AUTOSAR XML (schema 4-3-0)
standard types defined: uint8, uint8_DataConstr, uint16
package /ComponentTypes/FcaAdapSWC/Constants
  constant specification CS_FCAAdap_FCA_Output: value-spec=fields=[FCA_WrngLvlSta:0, FCA_VehStpReq:0, FCA_StbltActvReq:0, FCA_DclReqVal:0, FCA_PrefillActvReq:0, FCA_FullActvReq:0, FCA_TimetoCllsn:0, FCA_WrngTrgtDis:0, FCA_PartialActvReq:0]
package /ComponentTypes/FcaAdapSWC/DataTypes
  impl type FCA_OUTPUTS_T: category=STRUCTURE, type-emitter=RTE
    9 x element, all with category=TYPE_REFERENCE, implementation-data-type=uint8:
      FCA_WrngLvlSta
      FCA_VehStpReq
      FCA_StbltActvReq
      FCA_DclReqVal
      FCA_PrefillActvReq
      FCA_FullActvReq
      FCA_TimetoCllsn
      FCA_WrngTrgtDis
      FCA_PartialActvReq
package /ComponentTypes/FcaAdapSWC/PortInterfaces
  sender receiver interface IF_FCA_OUTPUT: invalidation-policy{data-element=DE_FcaAdapOutput, handle-invalid=DONT-INVALIDATE}
    data DE_FcaAdapOutput: type=FCA_OUTPUTS_T
package /ComponentTypes/HkmcVehicleOutputSWC
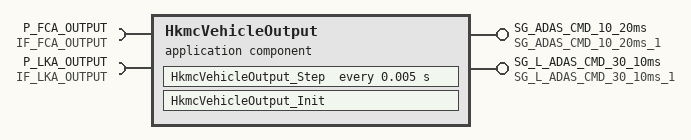
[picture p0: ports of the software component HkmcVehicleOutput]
  application sw component type HkmcVehicleOutput
    provide port SG_ADAS_CMD_10_20ms: nonqueued-sender-com-spec{data-element=SG_ADAS_CMD_10_20ms, init-value=fields=[ADAS_CMD_AlvCnt10Val:0, ADAS_CMD_Crc10Val:65535, FCA_DclReqVal:0, FCA_FullActvReq:0, FCA_HydrlcBstAsstReq:0, FCA_Jnctn_OnOffEquipSta:0, FCA_OnOffEquipSta:0, FCA_PartialActvReq:0, FCA_PrefillActvReq:0, FCA_RelVel:0, FCA_SnstvtyModRetVal:0, FCA_StbltActvReq:0, FCA_SysFlrSta:0, FCA_TimetoCllsn:0, FCA_VehStpReq:0, FCA_WrngLvlSta:0, FCA_WrngTrgtDis:0]}, provided-interface=SG_ADAS_CMD_10_20ms_1
    provide port SG_L_ADAS_CMD_30_10ms: nonqueued-sender-com-spec{data-element=SG_L_ADAS_CMD_30_10ms, init-value=fields=[ADAS_CMD_30_AlvCnt01Val:0, ADAS_CMD_30_Crc01Val:65535, Info_PedtrnDst_Copy_1:0, LKA_ActToiSta_Copy_1:0, LKA_HndsoffSnd_Copy_1:0, LKA_LHLnWrnSta_Copy_1:0, LKA_OptUsmSta_Copy_1:0, LKA_RcgSta_Copy_1:0, LKA_RHLnWrnSta_Copy_1:0, LKA_StrSnd_Copy_1:0, LKA_StrTqReqVal_Copy_1:1024, LKA_SysIndReq_Copy_1:0, LKA_SysWrn_Copy_1:0, LKA_ToiFltSta_Copy_1:0, LKA_UsmMod_Copy_1:0]}, provided-interface=SG_L_ADAS_CMD_30_10ms_1
    require port P_FCA_OUTPUT: nonqueued-receiver-com-spec{data-element=DE_FcaAdapOutput, filter=data-filter-type=ALWAYS, init-value=constant-reference=CS_FCAAdap_FCA_Output}, required-interface=IF_FCA_OUTPUT
    require port P_LKA_OUTPUT: nonqueued-receiver-com-spec{data-element=DE_LKA_OUTPUT, filter=data-filter-type=ALWAYS, init-value=constant-reference=CS_LKA_OUTPUT}, required-interface=IF_LKA_OUTPUT
    behavior HkmcVehicleOutput_InternalBehavior
      init event HkmcVehicleOutput_InitEvent: start-on-event=HkmcVehicleOutput_Init
      timing event HkmcVehicleOutput_Step_TE: start-on-event=HkmcVehicleOutput_Step, period=0.005
      runnable HkmcVehicleOutput_Init
        data-receive-point-by-arguments:
          access REC_P_FCA_OUTPUT_DE_FcaAdapOutput: accessed-variable=P_FCA_OUTPUT.DE_FcaAdapOutput
          access REC_P_LKA_OUTPUT_DE_LKA_OUTPUT: accessed-variable=P_LKA_OUTPUT.DE_LKA_OUTPUT
        data-send-points:
          access SEND_SG_ADAS_CMD_10_20ms_SG_ADAS_CMD_10_20ms: accessed-variable=SG_ADAS_CMD_10_20ms.SG_ADAS_CMD_10_20ms
          access SEND_SG_L_ADAS_CMD_30_10ms_SG_L_ADAS_CMD_30_10ms: accessed-variable=SG_L_ADAS_CMD_30_10ms.SG_L_ADAS_CMD_30_10ms
      runnable HkmcVehicleOutput_Step
        data-receive-point-by-arguments:
          access REC_P_FCA_OUTPUT_DE_FcaAdapOutput: accessed-variable=P_FCA_OUTPUT.DE_FcaAdapOutput
          access REC_P_LKA_OUTPUT_DE_LKA_OUTPUT: accessed-variable=P_LKA_OUTPUT.DE_LKA_OUTPUT
        data-send-points:
          access SEND_SG_ADAS_CMD_10_20ms_SG_ADAS_CMD_10_20ms: accessed-variable=SG_ADAS_CMD_10_20ms.SG_ADAS_CMD_10_20ms
          access SEND_SG_L_ADAS_CMD_30_10ms_SG_L_ADAS_CMD_30_10ms: accessed-variable=SG_L_ADAS_CMD_30_10ms.SG_L_ADAS_CMD_30_10ms
  swc implementation HkmcVehicleOutput_Implementation: behavior=HkmcVehicleOutput_InternalBehavior
    code-descriptors:
      code Default: artifact-descriptors=autosar-engineering-object={short-label=Default, category=SWSRC}
package /ComponentTypes/LkaAdapSWC/Constants
  constant specification CS_LKA_OUTPUT: value-spec=fields=[LKA_OptUsmSta_Copy_1:0, LKA_LHLnWrnSta_Copy_1:0, LKA_RHLnWrnSta_Copy_1:0]
package /ComponentTypes/LkaAdapSWC/DataTypes
  impl type LKA_OUTPUTS_T: category=STRUCTURE, type-emitter=RTE
    element LKA_OptUsmSta_Copy_1: implementation-data-type=uint8
    element LKA_LHLnWrnSta_Copy_1: implementation-data-type=uint8
    element LKA_RHLnWrnSta_Copy_1: implementation-data-type=uint8
package /ComponentTypes/LkaAdapSWC/PortInterfaces
  sender receiver interface IF_LKA_OUTPUT: invalidation-policy{data-element=DE_LKA_OUTPUT, handle-invalid=DONT-INVALIDATE}
    data DE_LKA_OUTPUT: type=LKA_OUTPUTS_T
package /DataTypes
  34 x impl type:
    ADAS_CMD_30_AlvCnt01Val: category=VALUE, base-type=DataType/uint8
    ADAS_CMD_30_Crc01Val: category=VALUE, base-type=uint16
    ADAS_CMD_AlvCnt10Val: category=VALUE, base-type=DataType/uint8
    ADAS_CMD_Crc10Val: category=VALUE, base-type=uint16
    FCA_DclReqVal: category=VALUE, base-type=DataType/uint8
    FCA_FullActvReq: category=VALUE, base-type=DataType/uint8, compu {0=Cx0_No_Full_act (No Full act), 1=Cx1_Full_act (Full act), 2=Cx2_Reserved, 3=Cx3_Error_Indicator (Error Indicator)}
    FCA_HydrlcBstAsstReq: category=VALUE, base-type=DataType/uint8, compu {0=Cx0_Standard_threshold (Standard threshold), 1=Cx1_Lowered_threshold_1 (Lowered threshold 1), 2=Cx2_Lowered_threshold_2 (Lowered threshold 2), 3=Cx3_Lowered_threshold_3 (Lowered threshold 3)}
    FCA_Jnctn_OnOffEquipSta: category=VALUE, base-type=DataType/uint8, compu {0=Cx0_Default, 1=Cx1_Off, 2=Cx2_On, 3=Cx3_Invalid}
    FCA_OnOffEquipSta: category=VALUE, base-type=DataType/uint8, compu {0=Cx0_Default, 1=Cx1_Off, 2=Cx2_Warning, 3=Cx3_Assist, 4=Cx4_Reserved, 5=Cx5_Reserved, 6=Cx6_Reserved, 7=Cx7_Invalid}
    FCA_PartialActvReq: category=VALUE, base-type=DataType/uint8, compu {0=Cx0_No_Partial_act (No Partial act), 1=Cx1_Partail_act_ (Partail act), 2=Cx2_Reserved, 3=Cx3_Error_Indicator (Error Indicator)}
    FCA_PrefillActvReq: category=VALUE, base-type=DataType/uint8, compu {0=Cx0_No_pre_fill (No pre-fill), 1=Cx1_Pre_fill_act (Pre-fill act), 2=Cx2_Reserved, 3=Cx3_Error_Indicator (Error Indicator)}
    FCA_RelVel: category=VALUE, base-type=uint16
    FCA_SnstvtyModRetVal: category=VALUE, base-type=DataType/uint8, compu {0=Cx0_Default, 1=Cx1_Late, 2=Cx2_Normal, 3=Cx3_Early, 4=Cx4_Reserved, 5=Cx5_Reserved, 6=Cx6_Reserved, 7=Cx7_Invalid}
    FCA_StbltActvReq: category=VALUE, base-type=DataType/uint8, compu {0=Cx0_Release_No_alert (Release No alert), 1=Cx1_Pre_crash_full_retraction (Pre-crash full retraction), 2=Cx2_Haptic_warning (Haptic warning), 3=Cx3_Reserved, 4=Cx4_Reserved, 5=Cx5_Reserved, 6=Cx6_Reserved, 7=Cx7_Reserved}
    FCA_SysFlrSta: category=VALUE, base-type=DataType/uint8, compu {0=Cx0_Normal, 1=Cx1_Temp_Unavailable_by_Camera (Temp. Unavailable by Camera), 2=Cx2_Temp_Unavailable_by_Radar (Temp. Unavailable by Radar), 3=Cx3_Service_Required (Service Required), 4=Cx4_Temp_Unavailable_by_Camera_Camera_only_ (Temp. Unavailable by Camera (Camera only)), 5=Cx5_Reserved, 6=Cx6_Reserved, 7=Cx7_Reserved}
    FCA_TimetoCllsn: category=VALUE, base-type=DataType/uint8
    FCA_VehStpReq: category=VALUE, base-type=DataType/uint8, compu {0=Cx0_No_request (No request), 1=Cx1_Stop_control_is_required (Stop control is required), 2=Cx2_Reserved, 3=Cx3_Error_Indicator (Error Indicator)}
    FCA_WrngLvlSta: category=VALUE, base-type=DataType/uint8, compu {0=Cx0_No_warning (No warning), 1=Cx1_Warning_level_1 (Warning level 1), 2=Cx2_Warning_level_2 (Warning level 2), 3=Cx3_Warning_level_3 (Warning level 3)}
    FCA_WrngTrgtDis:
      category=VALUE
      base-type=DataType/uint8
      compu {0=Cx00_No_warning (No warning), 1=Cx01_FCA_Pedestrian (FCA-Pedestrian), 2=Cx02_Reserved, 3=Cx03_FCA_Cyclist (FCA-Cyclist), 4=Cx04_Reserved, 5=Cx05_FCA_Car (FCA-Car), 6=Cx06_Reserved, 7=Cx07_FCA_JC_L_ (FCA-JC(L)), 8=Cx08_FCA_JC_ (FCA-JC®), 9=Cx09_Reserved, 10=Cx0A_Reserved, 11=Cx0B_FCA_JT_L_ (FCA-JT(L)), 12=Cx0C_FCA_JT_R_ (FCA-JT(R)), 13=Cx0D_Reserved, 14=Cx0E_Reserved}
    Info_PedtrnDst_Copy_1: category=VALUE, base-type=DataType/uint8
    LKA_ActToiSta_Copy_1: category=VALUE, base-type=DataType/uint8, compu {0=Cx0_De_activate_TOI (De-activate TOI), 1=Cx1_Activate_TOI (Activate TOI), 2=Cx2_Reserved, 3=Cx3_Error_indicator (Error indicator)}
    LKA_HndsoffSnd_Copy_1: category=VALUE, base-type=DataType/uint8, compu {0=Cx0_Off, 1=Cx1_Hands_off_Sound_Warning (Hands-off Sound Warning), 2=Cx2_Reserved, 3=Cx3_Reserved}
    LKA_LHLnWrnSta_Copy_1: category=VALUE, base-type=DataType/uint8, compu {0=Cx0_No_Warning (No Warning), 1=Cx1_Lane_Departure_Warning (Lane Departure Warning), 2=Cx2_Reserved, 3=Cx3_Reserved}
    LKA_OptUsmSta_Copy_1: category=VALUE, base-type=DataType/uint8, compu {0=Cx0_None_LKA_LDW_Option_Default_ (None LKA/LDW Option (Default)), 1=Cx1_LDW, 2=Cx2_LKA, 3=Cx3_Reserved, 4=Cx4_LDW_Only_None_LKA_ (LDW Only (None LKA)), 5=Cx5_LDW_only_OFF_None_LKA_ (LDW only OFF (None LKA)), 6=Cx6_LDW_LKA_OFF (LDW/LKA OFF), 7=Cx7_Invalid}
    LKA_RcgSta_Copy_1: category=VALUE, base-type=DataType/uint8, compu {0=Cx0_Not_Recognized (Not Recognized), 1=Cx1_Full_Lane_Recognized (Full Lane Recognized), 2=Cx2_Left_Line_Recognized (Left Line Recognized), 3=Cx3_Right_Line_Recognized (Right Line Recognized), 4=Cx4_Reserved, 5=Cx5_Reserved, 6=Cx6_Reserved, 7=Cx7_Reserved}
    LKA_RHLnWrnSta_Copy_1: category=VALUE, base-type=DataType/uint8, compu {0=Cx0_No_Warning (No Warning), 1=Cx1_Lane_Departure_Warning (Lane Departure Warning), 2=Cx2_Reserved, 3=Cx3_Reserved}
    LKA_StrSnd_Copy_1: category=VALUE, base-type=DataType/uint8, compu {0=Cx0_Off, 1=Cx1_Warning, 2=Cx2_Reserved, 3=Cx3_Reserved}
    LKA_StrTqReqVal_Copy_1: category=VALUE, base-type=uint16
    LKA_SysIndReq_Copy_1:
      category=VALUE
      base-type=DataType/uint8
      compu {0=Cx0_Off, 1=Cx1_Unavailable_Grey_On_ (Unavailable_(Grey On)), 2=Cx2_Lane_Recognized_Green_On_ (Lane Recognized_(Green On)), 3=Cx3_Lane_Departure_Green_Blink_ (Lane Departure_(Green Blink)), 4=Cx4_System_Fail_Orange_On_ (System Fail_(Orange On)), 5=Cx5_Not_Calibrated_Orange_Blink_ (Not Calibrated_(Orange Blink)), 6=Cx6_Regulation_Orange_On_ (Regulation_(Orange On)), 7=Cx7_Reserved}
    LKA_SysWrn_Copy_1:
      category=VALUE
      base-type=DataType/uint8
      compu {0=Cx0_No_Info (No Info), 1=Cx1_Reserved, 2=Cx2_Reserved, 3=Cx3_Reserved, 4=Cx4_Hands_Off_Warning_1 (Hands-Off Warning 1), 5=Cx5_Hands_Off_Warning_2 (Hands-Off Warning 2), 6=Cx6_Reserved, 7=Cx7_Reserved, 8=Cx8_Reserved, 9=Cx9_System_Automatic_off (System Automatic off), 10=CxA_Reserved, 11=CxB_Reserved, 12=CxC_Reserved, 13=CxD_Reserved, 14=CxE_Reserved, 15=CxF_System_Fail (System Fail)}
    LKA_ToiFltSta_Copy_1: category=VALUE, base-type=DataType/uint8, compu {0=Cx0_No_Fault (No Fault), 1=Cx1_Fault, 2=Cx2_Reserved, 3=Cx3_Error_indicatorr (Error indicatorr)}
    LKA_UsmMod_Copy_1: category=VALUE, base-type=DataType/uint8, compu {0=Cx0_NONE, 1=Cx1_LKA_1_mode (LKA 1 mode), 2=Cx2_LKA_2_mode (LKA 2 mode), 3=Cx3_LDW}
    SG_ADAS_CMD_10_20ms: category=STRUCTURE
      17 x element, all with category=TYPE_REFERENCE:
        ADAS_CMD_AlvCnt10Val: range raw 0..255, implementation-data-type=ADAS_CMD_AlvCnt10Val
        ADAS_CMD_Crc10Val: range raw 0..65535, implementation-data-type=ADAS_CMD_Crc10Val
        FCA_DclReqVal: implementation-data-type=FCA_DclReqVal
        FCA_FullActvReq: range raw 0..3, implementation-data-type=FCA_FullActvReq
        FCA_HydrlcBstAsstReq: range raw 0..3, implementation-data-type=FCA_HydrlcBstAsstReq
        FCA_Jnctn_OnOffEquipSta: range raw 0..3, implementation-data-type=FCA_Jnctn_OnOffEquipSta
        FCA_OnOffEquipSta: range raw 0..7, implementation-data-type=FCA_OnOffEquipSta
        FCA_PartialActvReq: range raw 0..3, implementation-data-type=FCA_PartialActvReq
        FCA_PrefillActvReq: range raw 0..3, implementation-data-type=FCA_PrefillActvReq
        FCA_RelVel: range raw 0..511, implementation-data-type=FCA_RelVel
        FCA_SnstvtyModRetVal: range raw 0..7, implementation-data-type=FCA_SnstvtyModRetVal
        FCA_StbltActvReq: range raw 0..7, implementation-data-type=FCA_StbltActvReq
        FCA_SysFlrSta: range raw 0..7, implementation-data-type=FCA_SysFlrSta
        FCA_TimetoCllsn: implementation-data-type=FCA_TimetoCllsn
        FCA_VehStpReq: range raw 0..3, implementation-data-type=FCA_VehStpReq
        FCA_WrngLvlSta: range raw 0..3, implementation-data-type=FCA_WrngLvlSta
        FCA_WrngTrgtDis: range raw 0..31, implementation-data-type=FCA_WrngTrgtDis
    SG_L_ADAS_CMD_30_10ms: category=STRUCTURE
      15 x element, all with category=TYPE_REFERENCE:
        ADAS_CMD_30_AlvCnt01Val: range raw 0..255, implementation-data-type=ADAS_CMD_30_AlvCnt01Val
        ADAS_CMD_30_Crc01Val: range raw 0..65535, implementation-data-type=ADAS_CMD_30_Crc01Val
        Info_PedtrnDst_Copy_1: range raw 0..7, implementation-data-type=Info_PedtrnDst_Copy_1
        LKA_ActToiSta_Copy_1: range raw 0..3, implementation-data-type=LKA_ActToiSta_Copy_1
        LKA_HndsoffSnd_Copy_1: range raw 0..3, implementation-data-type=LKA_HndsoffSnd_Copy_1
        LKA_LHLnWrnSta_Copy_1: range raw 0..3, implementation-data-type=LKA_LHLnWrnSta_Copy_1
        LKA_OptUsmSta_Copy_1: range raw 0..7, implementation-data-type=LKA_OptUsmSta_Copy_1
        LKA_RcgSta_Copy_1: range raw 0..7, implementation-data-type=LKA_RcgSta_Copy_1
        LKA_RHLnWrnSta_Copy_1: range raw 0..3, implementation-data-type=LKA_RHLnWrnSta_Copy_1
        LKA_StrSnd_Copy_1: range raw 0..3, implementation-data-type=LKA_StrSnd_Copy_1
        LKA_StrTqReqVal_Copy_1: range raw 0..2047, implementation-data-type=LKA_StrTqReqVal_Copy_1
        LKA_SysIndReq_Copy_1: range raw 0..7, implementation-data-type=LKA_SysIndReq_Copy_1
        LKA_SysWrn_Copy_1: range raw 0..15, implementation-data-type=LKA_SysWrn_Copy_1
        LKA_ToiFltSta_Copy_1: range raw 0..3, implementation-data-type=LKA_ToiFltSta_Copy_1
        LKA_UsmMod_Copy_1: range raw 0..3, implementation-data-type=LKA_UsmMod_Copy_1
package /PortInterfaces
  sender receiver interface SG_ADAS_CMD_10_20ms_1: invalidation-policy{data-element=SG_ADAS_CMD_10_20ms, handle-invalid=DONT-INVALIDATE}
    data SG_ADAS_CMD_10_20ms: type=SG_ADAS_CMD_10_20ms
  sender receiver interface SG_L_ADAS_CMD_30_10ms_1: invalidation-policy{data-element=SG_L_ADAS_CMD_30_10ms, handle-invalid=DONT-INVALIDATE}
    data SG_L_ADAS_CMD_30_10ms: type=SG_L_ADAS_CMD_30_10ms
